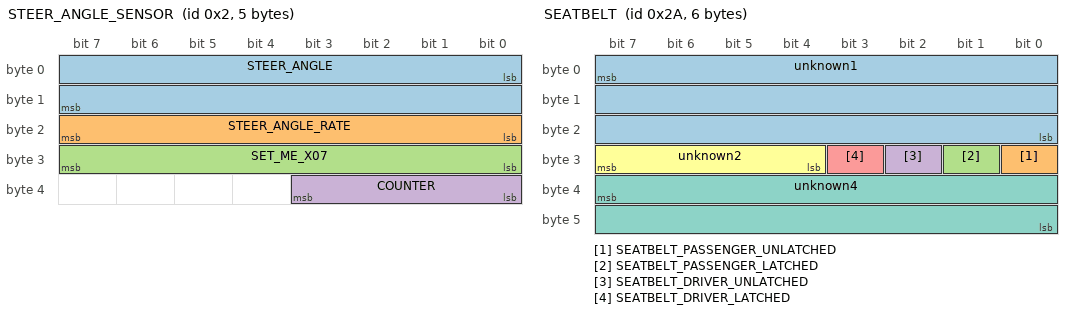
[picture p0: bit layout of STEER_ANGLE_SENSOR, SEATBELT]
BO_ 2 STEER_ANGLE_SENSOR: 5 XXX
 SG_ STEER_ANGLE : 0|16@1- (-0.1,0) [0|65535] "" XXX
 SG_ STEER_ANGLE_RATE : 16|8@1+ (1,0) [0|255] "" XXX
 SG_ SET_ME_X07 : 24|8@1+ (1,0) [0|255] "" XXX
 SG_ COUNTER : 32|4@1+ (1,0) [0|15] "" XXX

BO_ 42 SEATBELT: 6 XXX
 SG_ unknown1 : 7|24@0+ (1,0) [0|16777215] "" XXX
 SG_ SEATBELT_PASSENGER_UNLATCHED : 24|1@0+ (1,0) [0|1] "" XXX
 SG_ SEATBELT_PASSENGER_LATCHED : 25|1@0+ (1,0) [0|1] "" XXX
 SG_ SEATBELT_DRIVER_UNLATCHED : 26|1@0+ (1,0) [0|1] "" XXX
 SG_ SEATBELT_DRIVER_LATCHED : 27|1@1+ (1,0) [0|3] "" XXX
 SG_ unknown2 : 31|4@0+ (1,0) [0|15] "" XXX
 SG_ unknown4 : 39|16@0+ (1,0) [0|65535] "" XXX

BO_ 282 NEW_MSG_11A: 8 XXX

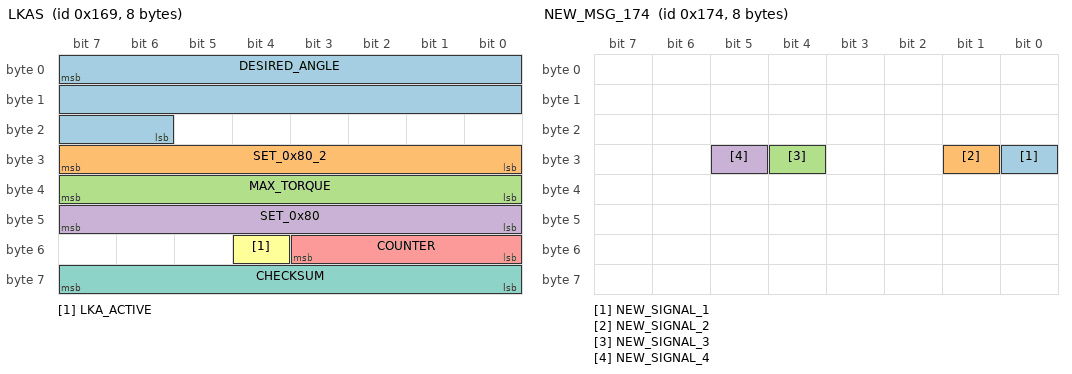
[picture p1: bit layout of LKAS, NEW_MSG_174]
BO_ 361 LKAS: 8 ADAS
 SG_ DESIRED_ANGLE : 7|18@0+ (-0.01,1310) [-1311.43|1310] "" XXX
 SG_ SET_0x80_2 : 31|8@0+ (1,0) [0|255] "" XXX
 SG_ MAX_TORQUE : 39|8@0+ (0.01,0) [0|255] "Nm" XXX
 SG_ SET_0x80 : 47|8@0+ (1,0) [0|255] "" XXX
 SG_ COUNTER : 51|4@0+ (1,0) [0|15] "" XXX
 SG_ LKA_ACTIVE : 52|1@0+ (1,0) [0|15] "" XXX
 SG_ CHECKSUM : 63|8@0+ (1,0) [0|255] "" XXX

BO_ 372 NEW_MSG_174: 8 XXX
 SG_ NEW_SIGNAL_1 : 24|1@0+ (1,0) [0|1] "" XXX
 SG_ NEW_SIGNAL_2 : 25|1@0+ (1,0) [0|1] "" XXX
 SG_ NEW_SIGNAL_3 : 28|1@0+ (1,0) [0|1] "" XXX
 SG_ NEW_SIGNAL_4 : 29|1@0+ (1,0) [0|1] "" XXX

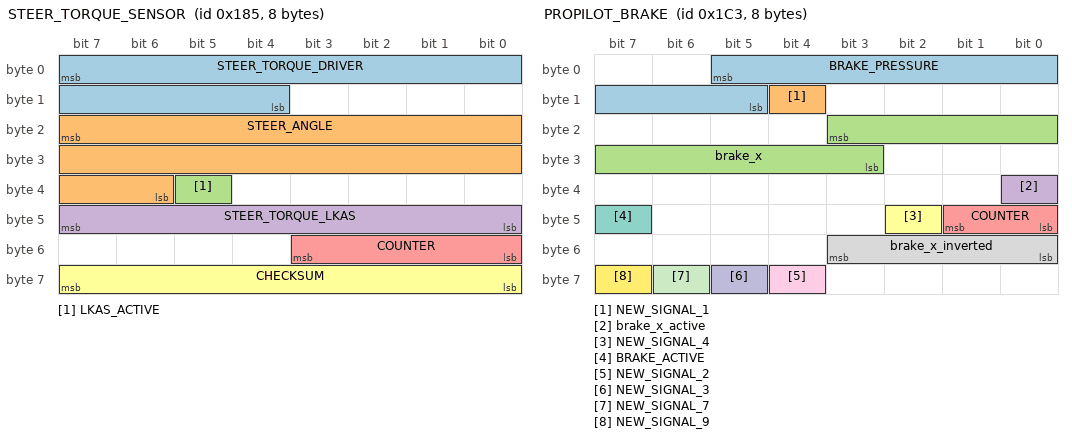
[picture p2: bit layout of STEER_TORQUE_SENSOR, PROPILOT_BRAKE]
BO_ 389 STEER_TORQUE_SENSOR: 8 XXX
 SG_ STEER_TORQUE_DRIVER : 7|12@0+ (-0.01,20.47) [0|4095] "Nm" XXX
 SG_ STEER_ANGLE : 23|18@0+ (-0.01,1310) [0|262143] "" XXX
 SG_ LKAS_ACTIVE : 37|1@0+ (1,0) [0|3] "" XXX
 SG_ STEER_TORQUE_LKAS : 47|8@0+ (1,0) [0|255] "" XXX
 SG_ COUNTER : 51|4@0+ (1,0) [0|15] "" XXX
 SG_ CHECKSUM : 63|8@0+ (1,0) [0|127] "" XXX

BO_ 451 PROPILOT_BRAKE: 8 XXX
 SG_ BRAKE_PRESSURE : 5|9@0+ (1,0) [0|511] "" XXX
 SG_ NEW_SIGNAL_1 : 12|1@0+ (1,0) [0|1] "" XXX
 SG_ brake_x : 19|9@0+ (1,0) [0|1] "" XXX
 SG_ brake_x_active : 32|1@0+ (1,0) [0|1] "" XXX
 SG_ COUNTER : 41|2@0+ (1,0) [0|1] "" XXX
 SG_ NEW_SIGNAL_4 : 42|1@0+ (1,0) [0|1] "" XXX
 SG_ BRAKE_ACTIVE : 47|1@0+ (1,0) [0|1] "" XXX
 SG_ brake_x_inverted : 51|4@0+ (1,0) [0|1] "" XXX
 SG_ NEW_SIGNAL_2 : 60|1@0+ (1,0) [0|1] "" XXX
 SG_ NEW_SIGNAL_3 : 61|1@0+ (1,0) [0|1] "" XXX
 SG_ NEW_SIGNAL_7 : 62|1@0+ (1,0) [0|1] "" XXX
 SG_ NEW_SIGNAL_9 : 63|1@0+ (1,0) [0|1] "" XXX

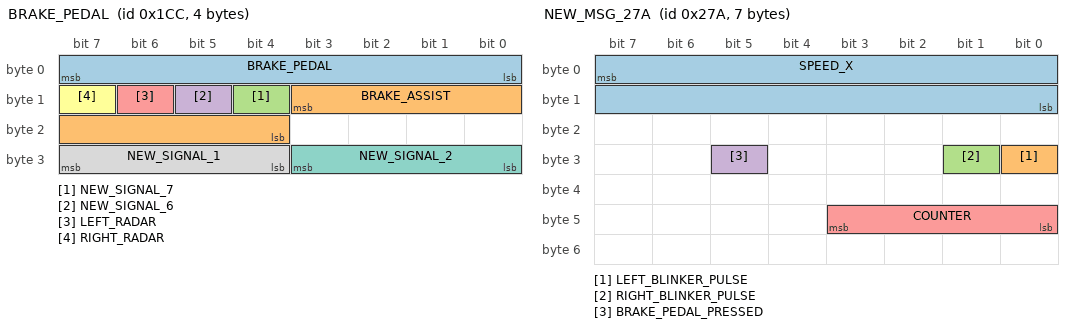
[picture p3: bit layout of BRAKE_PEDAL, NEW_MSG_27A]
BO_ 460 BRAKE_PEDAL: 4 XXX
 SG_ BRAKE_PEDAL : 7|8@0+ (1,0) [0|256] "" XXX
 SG_ BRAKE_ASSIST : 11|8@0+ (1,0) [0|1] "" XXX
 SG_ NEW_SIGNAL_7 : 12|1@0+ (1,0) [0|1] "" XXX
 SG_ NEW_SIGNAL_6 : 13|1@0+ (1,0) [0|1] "" XXX
 SG_ LEFT_RADAR : 14|1@0+ (1,0) [0|1] "" XXX
 SG_ RIGHT_RADAR : 15|1@0+ (1,0) [0|1] "" XXX
 SG_ NEW_SIGNAL_2 : 24|4@1+ (1,0) [0|15] "" XXX
 SG_ NEW_SIGNAL_1 : 28|4@1+ (1,0) [0|15] "" XXX

BO_ 569 CRUISE_THROTTLE: 8 XXX
 SG_ GAS_PEDAL : 7|8@0+ (1,0) [0|255] "" XXX
 SG_ GAS_PEDAL_INVERTED : 15|8@0+ (1,0) [0|255] "" XXX
 SG_ GAS_PEDAL_RELEASED : 16|1@0+ (1,0) [0|1] "" XXX
 SG_ LKAS_AVAILABLE : 17|1@0+ (1,0) [0|1] "" XXX
 SG_ ACC_IN_STANDBY : 18|1@0+ (1,0) [0|63] "" XXX
 SG_ CRUISE_AVAILABLE : 22|1@1+ (1,0) [0|3] "" XXX
 SG_ CRUISE_AVAILABLE_INVERTED : 23|1@0+ (1,0) [0|1] "" XXX
 SG_ PROPILOT_BUTTON : 24|1@0+ (1,0) [0|1] "" XXX
 SG_ CANCEL_BUTTON : 25|1@0+ (1,0) [0|1] "" XXX
 SG_ FOLLOW_DISTANCE_BUTTON : 26|1@0+ (1,0) [0|1] "" XXX
 SG_ SET_BUTTON : 27|1@0+ (1,0) [0|1] "" XXX
 SG_ RES_BUTTON : 28|1@0+ (1,0) [0|1] "" XXX
 SG_ NO_BUTTON_PRESSED : 29|1@0+ (1,0) [0|1] "" XXX
 SG_ COUNTER : 32|2@1+ (1,0) [0|3] "" XXX
 SG_ PARKING_GEAR : 34|1@0+ (1,0) [0|1] "" XXX
 SG_ USER_BRAKE_PRESSED : 37|1@0+ (1,0) [0|1] "" XXX
 SG_ USER_BRAKE_PRESSED_INVERTED : 38|1@0+ (1,0) [0|1] "" XXX
 SG_ GAS_PEDAL2 : 47|10@0+ (1,0) [0|255] "" XXX
 SG_ GAS_PEDAL2_INVERTED : 53|10@0+ (1,0) [0|1] "" XXX

BO_ 634 NEW_MSG_27A: 7 ADAS
 SG_ SPEED_X : 7|16@0+ (0.1,0) [0|65535] "KPH" XXX
 SG_ LEFT_BLINKER_PULSE : 24|1@0+ (1,0) [0|1] "" XXX
 SG_ RIGHT_BLINKER_PULSE : 25|1@0+ (1,0) [0|1] "" XXX
 SG_ BRAKE_PEDAL_PRESSED : 29|1@0+ (1,0) [0|1] "" XXX
 SG_ COUNTER : 40|4@1+ (1,0) [0|15] "" XXX

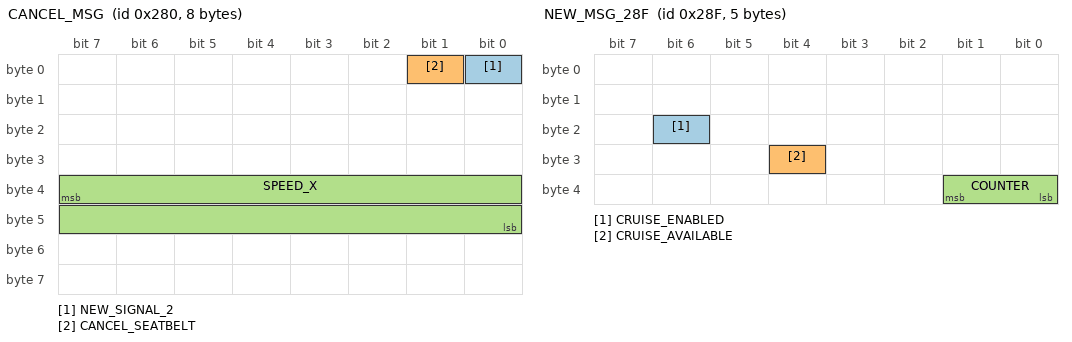
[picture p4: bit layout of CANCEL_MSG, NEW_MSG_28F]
BO_ 640 CANCEL_MSG: 8 XXX
 SG_ NEW_SIGNAL_2 : 0|1@0+ (1,0) [0|1] "" XXX
 SG_ CANCEL_SEATBELT : 1|1@0+ (1,0) [0|1] "" XXX
 SG_ SPEED_X : 39|16@0+ (1,0) [0|1023] "KPH" XXX

BO_ 644 WHEEL_SPEEDS_FRONT: 8 XXX
 SG_ WHEEL_SPEED_FR : 7|16@0+ (0.005,0) [0|65535] "KPH" XXX
 SG_ WHEEL_SPEED_FL : 23|16@0+ (0.005,0) [0|65535] "KPH" XXX

BO_ 645 WHEEL_SPEEDS_REAR: 8 XXX
 SG_ WHEEL_SPEED_RR : 7|16@0+ (0.005,0) [0|65535] "KPH" XXX
 SG_ WHEEL_SPEED_RL : 23|16@0+ (0.005,0) [0|65535] "KPH" XXX

BO_ 654 NEW_MSG_28E: 6 XXX
 SG_ PROPILOT_BRAKE_ACTIVE : 16|1@0+ (1,0) [0|1] "" XXX
 SG_ COUNTER : 41|2@1+ (1,0) [0|3] "" XXX

BO_ 655 NEW_MSG_28F: 5 XXX
 SG_ CRUISE_ENABLED : 22|1@0+ (1,0) [0|1] "" XXX
 SG_ CRUISE_AVAILABLE : 28|1@0+ (1,0) [0|1] "" XXX
 SG_ COUNTER : 32|2@1+ (1,0) [0|3] "" XXX

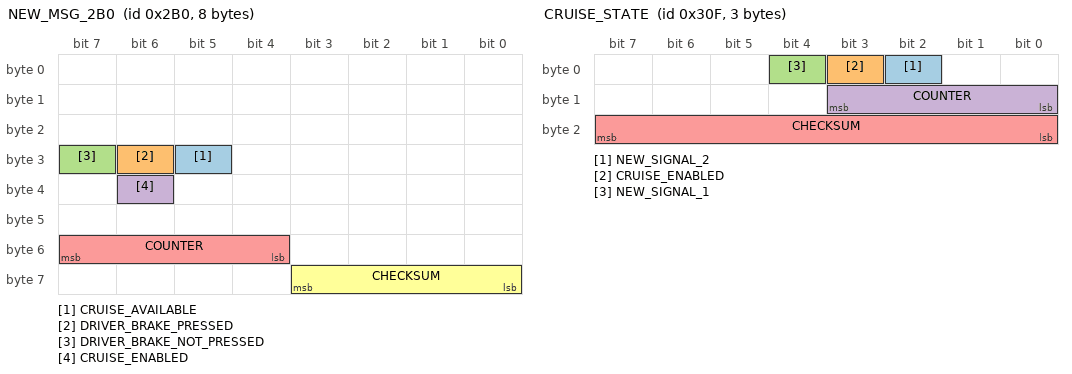
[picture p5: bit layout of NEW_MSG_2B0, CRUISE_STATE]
BO_ 688 NEW_MSG_2B0: 8 XXX
 SG_ CRUISE_AVAILABLE : 29|1@0+ (1,0) [0|1] "" XXX
 SG_ DRIVER_BRAKE_PRESSED : 30|1@0+ (1,0) [0|1] "" XXX
 SG_ DRIVER_BRAKE_NOT_PRESSED : 31|1@0+ (1,0) [0|1] "" XXX
 SG_ CRUISE_ENABLED : 38|1@0+ (1,0) [0|1] "" XXX
 SG_ COUNTER : 52|4@1+ (1,0) [0|15] "" XXX
 SG_ CHECKSUM : 59|4@0+ (1,0) [0|15] "" XXX

BO_ 689 PROPILOT_HUD: 8 ADAS
 SG_ unknown02 : 1|2@0+ (1,0) [0|3] "" XXX
 SG_ FOLLOW_DISTANCE : 3|2@0+ (1,0) [0|3] "" XXX
 SG_ unknown05 : 5|2@0+ (1,0) [0|3] "" XXX
 SG_ SPEED_SET_ICON : 7|2@0+ (1,0) [0|3] "" XXX
 SG_ unknown08 : 8|7@0+ (1,0) [0|63] "" XXX
 SG_ LARGE_WARNING_FLASHING : 9|1@0+ (1,0) [0|1] "" XXX
 SG_ SIDE_RADAR_ERROR_FLASHING1 : 10|1@0+ (1,0) [0|1] "" XXX
 SG_ SIDE_RADAR_ERROR_FLASHING2 : 11|1@0+ (1,0) [0|1] "" XXX
 SG_ RIGHT_LANE_YELLOW_FLASH : 12|1@0+ (1,0) [0|1] "" XXX
 SG_ LEFT_LANE_YELLOW_FLASH : 13|1@0+ (1,0) [0|1] "" XXX
 SG_ LEAD_CAR : 14|1@0+ (1,0) [0|1] "" XXX
 SG_ LEAD_CAR_ERROR : 15|1@0+ (1,0) [0|1] "" XXX
 SG_ FRONT_RADAR_ERROR : 16|1@0+ (1,0) [0|1] "" XXX
 SG_ FRONT_RADAR_ERROR_FLASHING : 17|1@0+ (1,0) [0|1] "" XXX
 SG_ RIGHT_LANE_GREEN : 24|1@0+ (1,0) [0|1] "" XXX
 SG_ LEFT_LANE_GREEN : 25|1@0+ (1,0) [0|1] "" XXX
 SG_ unknown26 : 26|1@0+ (1,0) [0|1] "" XXX
 SG_ SIDE_RADAR_ERROR_FLASHING3 : 27|1@0+ (1,0) [0|1] "" XXX
 SG_ unknown28 : 28|1@0+ (1,0) [0|1] "" XXX
 SG_ LKAS_ERROR_FLASHING : 29|1@0+ (1,0) [0|1] "" XXX
 SG_ SET_SPEED : 39|8@0+ (1,0) [0|255] "" XXX
 SG_ SMALL_STEERING_WHEEL_ICON : 42|3@0+ (1,0) [0|7] "" XXX
 SG_ unknown43 : 43|1@0+ (1,0) [0|1] "" XXX
 SG_ SAFETY_SHIELD_ACTIVE : 44|1@0+ (1,0) [0|1] "" XXX
 SG_ AUDIBLE_TONE : 47|3@0+ (1,0) [0|8] "" XXX
 SG_ unknown59 : 59|4@0+ (1,0) [0|15] "" XXX
 SG_ LARGE_STEERING_WHEEL_ICON : 61|2@0+ (1,0) [0|3] "" XXX
 SG_ RIGHT_LANE_GREEN_FLASH : 62|1@0+ (1,0) [0|1] "" XXX
 SG_ LEFT_LANE_GREEN_FLASH : 63|1@0+ (1,0) [0|1] "" XXX

BO_ 724 NEW_MSG_2D4: 6 XXX
 SG_ COUNTER : 33|2@0+ (1,0) [0|3] "" XXX
 SG_ CRUISE_ENABLED : 39|1@0+ (1,0) [0|1] "" XXX

BO_ 783 CRUISE_STATE: 3 ADAS
 SG_ NEW_SIGNAL_2 : 2|1@0+ (1,0) [0|1] "" XXX
 SG_ CRUISE_ENABLED : 3|1@0+ (1,0) [0|1] "" ADAS
 SG_ NEW_SIGNAL_1 : 4|1@0+ (1,0) [0|1] "" XXX
 SG_ COUNTER : 8|4@1+ (1,0) [0|15] "" XXX
 SG_ CHECKSUM : 16|8@1+ (1,0) [0|255] "" XXX

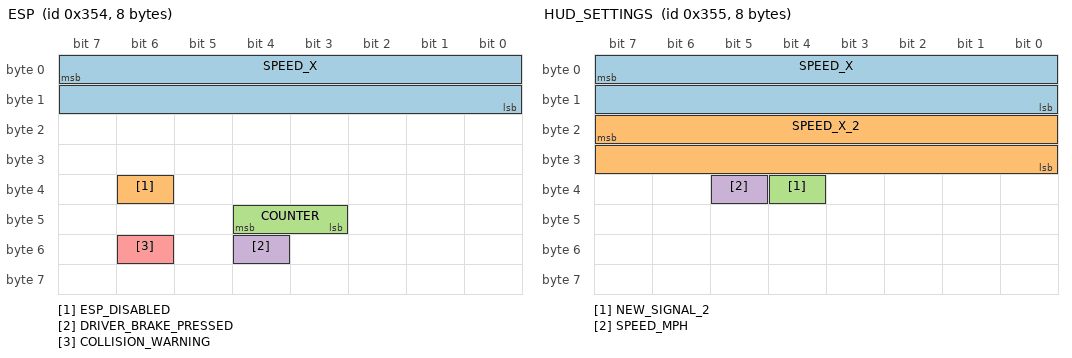
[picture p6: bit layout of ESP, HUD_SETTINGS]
BO_ 852 ESP: 8 XXX
 SG_ SPEED_X : 7|16@0+ (1,0) [0|1] "" XXX
 SG_ ESP_DISABLED : 38|1@0+ (1,0) [0|1] "" XXX
 SG_ COUNTER : 43|2@1+ (1,0) [0|3] "" XXX
 SG_ DRIVER_BRAKE_PRESSED : 52|1@0+ (1,0) [0|1] "" XXX
 SG_ COLLISION_WARNING : 54|1@0+ (1,0) [0|1] "" XXX

BO_ 853 HUD_SETTINGS: 8 XXX
 SG_ SPEED_X : 7|16@0+ (1,0) [0|16383] "" XXX
 SG_ SPEED_X_2 : 23|16@0+ (1,0) [0|1] "" XXX
 SG_ NEW_SIGNAL_2 : 36|1@0+ (1,0) [0|1] "" XXX
 SG_ SPEED_MPH : 37|1@0+ (1,0) [0|1] "" XXX

BO_ 856 LIGHTS: 8 XXX
 SG_ LEFT_BLINKER : 17|1@0+ (1,0) [0|1] "" XXX
 SG_ RIGHT_BLINKER : 18|1@0+ (1,0) [0|1] "" XXX

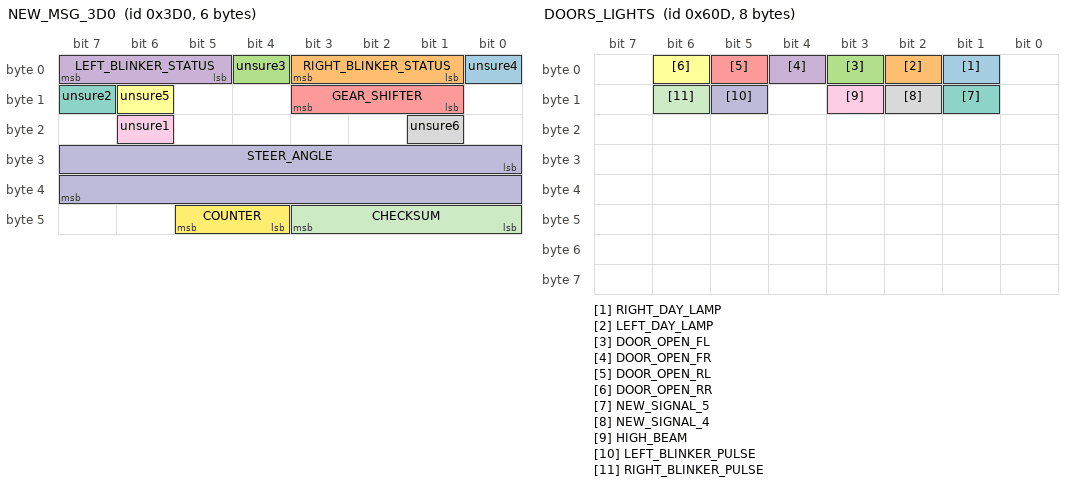
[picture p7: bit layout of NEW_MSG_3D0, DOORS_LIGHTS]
BO_ 976 NEW_MSG_3D0: 6 XXX
 SG_ unsure4 : 0|1@0+ (1,0) [0|1] "" XXX
 SG_ RIGHT_BLINKER_STATUS : 3|3@0+ (1,0) [0|7] "" XXX
 SG_ unsure3 : 4|1@0+ (1,0) [0|1] "" XXX
 SG_ LEFT_BLINKER_STATUS : 5|3@1+ (1,0) [0|7] "" XXX
 SG_ GEAR_SHIFTER : 9|3@1+ (1,0) [0|7] "" XXX
 SG_ unsure5 : 14|1@0+ (1,0) [0|1] "" XXX
 SG_ unsure2 : 15|1@0+ (1,0) [0|1] "" XXX
 SG_ unsure6 : 17|1@0+ (1,0) [0|1] "" XXX
 SG_ unsure1 : 22|1@0+ (1,0) [0|1] "" XXX
 SG_ STEER_ANGLE : 24|16@1- (-0.1,0) [0|65535] "deg" XXX
 SG_ CHECKSUM : 43|4@0+ (1,0) [0|15] "" XXX
 SG_ COUNTER : 44|2@1+ (1,0) [0|3] "" XXX

BO_ 1008 LEFT_BSW: 7 XXX
 SG_ WARNING_STATUS : 3|4@0+ (1,0) [0|15] "" XXX

BO_ 1011 RIGHT_BSW: 7 XXX
 SG_ WARNING_STATUS : 3|4@0+ (1,0) [0|15] "" XXX

BO_ 1057 GEARBOX: 3 XXX
 SG_ GEAR_SHIFTER : 5|3@0+ (1,0) [0|255] "" XXX

BO_ 1227 LKAS_SETTINGS: 8 ADAS
 SG_ LKAS_ENABLED : 51|1@0+ (1,0) [0|1] "" XXX

BO_ 1228 PROPILOT_HUD_INFO_MSG: 8 ADAS
 SG_ NA_HIGH_ACCEL_TEMP : 0|1@0+ (1,0) [0|1] "" XXX
 SG_ unknown07 : 7|7@0+ (1,0) [0|127] "" XXX
 SG_ SIDE_RADAR_NA_HIGH_CABIN_TEMP : 8|1@0+ (1,0) [0|1] "" XXX
 SG_ unknown10 : 10|2@0+ (1,0) [0|3] "" XXX
 SG_ SIDE_RADAR_MALFUNCTION : 11|1@0+ (1,0) [0|1] "" XXX
 SG_ LKAS_MALFUNCTION : 12|1@0+ (1,0) [0|1] "" XXX
 SG_ FRONT_RADAR_MALFUNCTION : 13|1@0+ (1,0) [0|1] "" XXX
 SG_ SIDE_RADAR_NA_CLEAN_REAR_CAMERA : 14|1@0+ (1,0) [0|1] "" XXX
 SG_ unknown15 : 15|1@0+ (1,0) [0|1] "" XXX
 SG_ NA_POOR_ROAD_CONDITIONS : 16|1@0+ (1,0) [0|1] "" XXX
 SG_ CURRENTLY_UNAVAILABLE : 17|1@0+ (1,0) [0|1] "" XXX
 SG_ SAFETY_SHIELD_OFF : 18|1@0+ (1,0) [0|1] "" XXX
 SG_ unknown19 : 19|1@0+ (1,0) [0|1] "" XXX
 SG_ FRONT_COLLISION_NA_FRONT_RADAR_OBSTRUCTION : 20|1@0+ (1,0) [0|1] "" XXX
 SG_ unknown23 : 23|3@0+ (1,0) [0|7] "" XXX
 SG_ PEDAL_MISSAPPLICATION_SYSTEM_ACTIVATED : 24|1@0+ (1,0) [0|1] "" XXX
 SG_ SIDE_IMPACT_NA_RADAR_OBSTRUCTION : 25|1@0+ (1,0) [0|1] "" XXX
 SG_ unknown31 : 31|6@0+ (1,0) [0|63] "" XXX
 SG_ unknown32 : 32|1@0+ (1,0) [0|1] "" XXX
 SG_ WARNING_DO_NOT_ENTER : 33|1@0+ (1,0) [0|1] "" XXX
 SG_ SIDE_IMPACT_SYSTEM_OFF : 34|1@0+ (1,0) [0|1] "" XXX
 SG_ SIDE_IMPACT_MALFUNCTION : 35|1@0+ (1,0) [0|1] "" XXX
 SG_ FRONT_COLLISION_MALFUNCTION : 36|1@0+ (1,0) [0|1] "" XXX
 SG_ SIDE_RADAR_MALFUNCTION2 : 37|1@0+ (1,0) [0|1] "" XXX
 SG_ LKAS_MALFUNCTION2 : 38|1@0+ (1,0) [0|1] "" XXX
 SG_ FRONT_RADAR_MALFUNCTION2 : 39|1@0+ (1,0) [0|1] "" XXX
 SG_ PROPILOT_NA_MSGS : 42|3@0+ (1,0) [0|7] "" XXX
 SG_ BOTTOM_MSG : 45|3@0+ (1,0) [0|7] "" XXX
 SG_ unknown46 : 46|1@0+ (1,0) [0|1] "" XXX
 SG_ HANDS_ON_WHEEL_WARNING : 47|1@0+ (1,0) [0|1] "" XXX
 SG_ unknown50 : 50|3@0+ (1,0) [0|7] "" XXX
 SG_ WARNING_STEP_ON_BRAKE_NOW : 51|1@0+ (1,0) [0|1] "" XXX
 SG_ PROPILOT_NA_FRONT_CAMERA_OBSTRUCTED : 52|1@0+ (1,0) [0|1] "" XXX
 SG_ PROPILOT_NA_HIGH_CABIN_TEMP : 53|1@0+ (1,0) [0|1] "" XXX
 SG_ WARNING_PROPILOT_MALFUNCTION : 54|1@0+ (1,0) [0|3] "" XXX
 SG_ unknown55 : 55|1@0+ (1,0) [0|1] "" XXX
 SG_ unknown61 : 61|6@0+ (1,0) [0|63] "" XXX
 SG_ ACC_UNAVAILABLE_HIGH_CABIN_TEMP : 62|1@0+ (1,0) [0|1] "" XXX
 SG_ ACC_NA_FRONT_CAMERA_IMPARED : 63|1@0+ (1,0) [0|1] "" XXX

BO_ 1549 DOORS_LIGHTS: 8 XXX
 SG_ RIGHT_DAY_LAMP : 1|1@0+ (1,0) [0|1] "" XXX
 SG_ LEFT_DAY_LAMP : 2|1@0+ (1,0) [0|1] "" XXX
 SG_ DOOR_OPEN_FL : 3|1@0+ (1,0) [0|1] "" XXX
 SG_ DOOR_OPEN_FR : 4|1@0+ (1,0) [0|1] "" XXX
 SG_ DOOR_OPEN_RL : 5|1@0+ (1,0) [0|1] "" XXX
 SG_ DOOR_OPEN_RR : 6|1@0+ (1,0) [0|1] "" XXX
 SG_ NEW_SIGNAL_5 : 9|1@0+ (1,0) [0|1] "" XXX
 SG_ NEW_SIGNAL_4 : 10|1@0+ (1,0) [0|1] "" XXX
 SG_ HIGH_BEAM : 11|1@0+ (1,0) [0|1] "" XXX
 SG_ LEFT_BLINKER_PULSE : 13|1@0+ (1,0) [0|1] "" XXX
 SG_ RIGHT_BLINKER_PULSE : 14|1@0+ (1,0) [0|1] "" XXX

BO_ 1856 ABS_QUERY: 8 XXX

BO_ 1859 BCM_QUERY: 8 XXX

BO_ 1860 HVAC_QUERY: 8 XXX

BO_ 1888 ABS_RESPONSE: 8 XXX

BO_ 1891 BCM_RESPONSE: 8 XXX

BO_ 1892 HVAC_RESPONSE: 8 XXX

BO_ 1943 VCM_QUERY: 8 XXX

BO_ 1946 VCM_RESPONSE: 8 XXX

CM_ SG_ 640 SPEED_X "Simmilar to 27A forward speed";
CM_ SG_ 853 NEW_SIGNAL_2 "KPH?";
VAL_ 689 FOLLOW_DISTANCE 0 "NO_FOLLOW_DISTANCE" 1 "FOLLOW_DISTANCE_1" 2 "FOLLOW_DISTANCE_2" 3 "FOLLOW_DISTANCE_3";
VAL_ 689 SMALL_STEERING_WHEEL_ICON 0 "NO_ICON" 1 "GRAY_ICON" 2 "GRAY_ICON_FLASHING" 3 "GREEN_ICON" 4 "GREEN_ICON_FLASHING" 5 "RED_ICON" 6 "RED_ICON_FLASHING" 7 "YELLOW_ICON";
VAL_ 689 AUDIBLE_TONE 0 "NO_TONE" 1 "CONT" 2 "FAST_BEEP_CONT" 3 "TRIPLE_FAST_BEEP_CONT" 4 "SLOW_BEEP_CONT" 5 "QUAD_SLOW_BEEP_CONT" 6 "SINGLE_BEEP_ONCE" 7 "DOUBLE_BEEP_ONCE";
VAL_ 689 LARGE_STEERING_WHEEL_ICON 0 "NO_STEERINGWHEEL" 1 "GRAY_STEERINGWHEEL" 2 "GREEN_STEERINGWHEEL" 3 "GREEN_STEERINGWHEEL_FLASHING";
VAL_ 976 RIGHT_BLINKER_STATUS 3 "Off" 1 "On";
VAL_ 976 LEFT_BLINKER_STATUS 3 "Off" 1 "On";
VAL_ 976 GEAR_SHIFTER 7 "B" 4 "D" 3 "N" 2 "R" 1 "P";
VAL_ 1008 WARNING_STATUS 13 "LIT_INDICATOR" 0 "UNLIT_INDICATOR" 5 "FLASH_INDICATOR";
VAL_ 1011 WARNING_STATUS 13 "LIT_INDICATOR" 0 "UNLIT_INDICATOR" 5 "FLASH_INDICATOR";
VAL_ 1057 GEAR_SHIFTER 7 "B" 4 "D" 3 "N" 2 "R" 1 "P";
VAL_ 1228 PROPILOT_NA_MSGS 0 "NO_MSG" 1 "NA_FRONT_CAMERA_IMPARED" 2 "STEERING_ASSIST_ON_STANDBY" 3 "NA_PARKING_ASSIST_ENABLED" 4 "STEER_ASSIST_CURRENTLY_NA" 5 "NA_BAD_WEATHER" 6 "NA_PARK_BRAKE_ON" 7 "NA_SEATBELT_NOT_FASTENED";
VAL_ 1228 BOTTOM_MSG 0 "OK_STEER_ASSIST_SETTINGS" 1 "NO_MSG" 2 "PRESS_SET_TO_SET_SPEED" 3 "PRESS_RES_SET_TO_CHANGE_SPEED" 4 "PRESS_RES_TO_RESTART" 5 "NO_MSG" 6 "CRUISE_NOT_AVAIL" 7 "NO_MSG";
